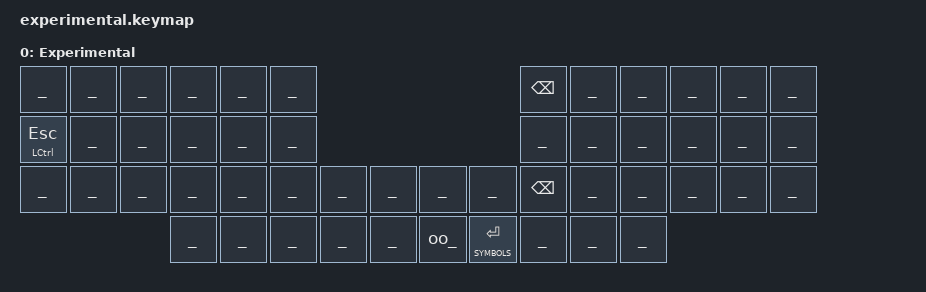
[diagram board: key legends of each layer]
/ {
    keymap {
        compatible = "zmk,keymap";
        experimental {
            label = "Experimental";
            bindings = <
//                ╭─────────┬─────┬─────┬─────┬─────┬─────╮                                     ╭─────┬─────┬─────┬─────┬─────┬─────╮
//                │         │     │     │     │     │     │                                     │  ⌫  │     │     │     │     │     │
//                ├─────────┼─────┼─────┼─────┼─────┼─────┤                                     ├─────┼─────┼─────┼─────┼─────┼─────┤
//                │  ⌃ │ ⎋  │     │     │     │     │     │                                     │     │     │     │     │     │     │
//                ├─────────┼─────┼─────┼─────┼─────┼─────┼─────┬─────╮   ╭─────┬───────────────┼─────┼─────┼─────┼─────┼─────┼─────┤
//                │         │     │     │     │     │     │     │     │   │     │               │  ⌫  │     │     │     │     │     │
//                ╰─────────┴─────┴─────┼─────┼─────┼─────┼─────┼─────┤   ├─────┼───────────────┼─────┼─────┼─────┼─────┴─────┴─────╯
//                                      │     │     │     │     │     │   │ --- │  SYMBOLS│ ⏎  │     │     │     │                  
//                                      ╰─────┴─────┴─────┴─────┴─────╯   ╰─────┴───────────────┴─────┴─────┴─────╯                  
              ____                ____   ____   ____   ____   ____                                                   &kp BSPC   ____   ____   ____   ____   ____
              &mt_sat LCTRL ESC   ____   ____   ____   ____   ____                                                   ____       ____   ____   ____   ____   ____
              ____                ____   ____   ____   ____   ____   ____   ____       ____   ____                   &kp BSPC   ____   ____   ____   ____   ____
                                                ____   ____   ____   ____   ____       _oo_   &lt_cyan SYMBOLS RET   ____       ____   ____                     
            >;
        };
	};
};
